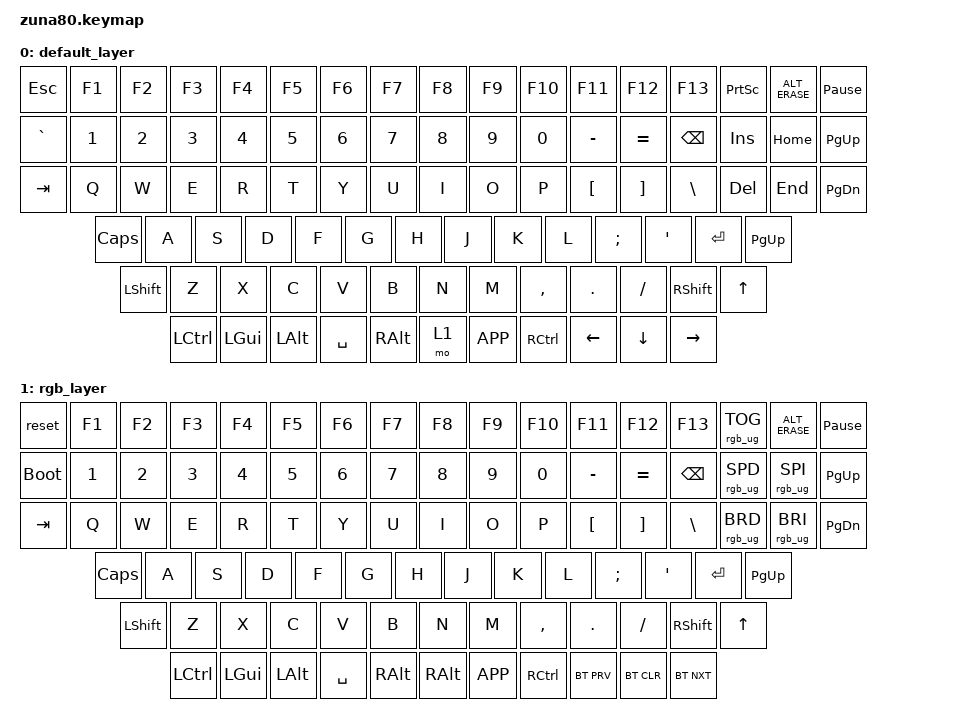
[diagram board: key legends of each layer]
/*
 * Copyright (c) 2021 Nick Winanschosen
 *
 * SPDX-License-Identifier: MIT
 */

#include <behaviors.dtsi>
#include <dt-bindings/zmk/keys.h>
#include <dt-bindings/zmk/rgb.h>
#include <dt-bindings/zmk/bt.h>
#include <dt-bindings/zmk/outputs.h>

/ {
	keymap {
		compatible = "zmk,keymap";
		
		 default_layer {
             bindings = <
        &kp ESC     &kp F1 &kp F2 &kp F3 &kp F4 &kp F5 &kp F6 &kp F7 &kp F8 &kp F9 &kp F10 &kp F11 &kp F12 &kp F13       &kp PSCRN &kp ALT_ERASE &kp PAUSE_BREAK
	&kp GRAVE  &kp N1 &kp N2 &kp N3 &kp N4 &kp N5 &kp N6 &kp N7 &kp N8 &kp N9 &kp N0 &kp MINUS &kp EQUAL  &kp BSPC      &kp INS &kp HOME &kp PG_UP
	&kp TAB  &kp Q  &kp W  &kp E  &kp R  &kp T  &kp Y  &kp U  &kp I  &kp O  &kp P  &kp LBKT  &kp RBKT  &kp BSLH          &kp DEL &kp END &kp PG_DN
	&kp CLCK  &kp A  &kp S  &kp D  &kp F  &kp G  &kp H  &kp J  &kp K  &kp L  &kp SEMI &kp SQT &kp RET &kp PG_UP
	&kp LSHFT   &kp Z  &kp X  &kp C  &kp V  &kp B  &kp N  &kp M  &kp COMMA &kp DOT &kp FSLH   &kp RSHFT                           &kp UP 
	&kp LCTRL &kp LGUI &kp LALT             &kp SPACE                     &kp RALT    &mo 1   &kp K_APP &kp RCTRL        &kp LEFT &kp DOWN &kp RIGHT
			>;
		

            
		};

		rgb_layer {
// ------------------------------------------------------------------------------------------------
// | BT CLR | F1  | F2  | F3  | F4  | F5  | F6  | F7  | F8  | F9  | F10  | F11 | F12 | EFFECT REV |
// |  BT 1   |   |  UP |   | HUEUP | SATUP | BRIUP | SPDUP |   |     |    |     |     |           |
// |   BT 2   | LT |  DN  | RT | HUEDN | SATDN | BRIDN | SPDDN |   |     |   |     |  EFFECT FORW |
// |    BT 3     |     |      |      |     |     |     |     |     |     |     |                  |
// |   BT 4  |      |      |             TOG RGB                | PRT SCR |       |       |  DEL  |
// ------------------------------------------------------------------------------------------------
			bindings = <
	&reset     &kp F1 &kp F2 &kp F3 &kp F4 &kp F5 &kp F6 &kp F7 &kp F8 &kp F9 &kp F10 &kp F11 &kp F12 &kp F13       &rgb_ug RGB_TOG&kp ALT_ERASE &kp PAUSE_BREAK
	&bootloader  &kp N1 &kp N2 &kp N3 &kp N4 &kp N5 &kp N6 &kp N7 &kp N8 &kp N9 &kp N0 &kp MINUS &kp EQUAL  &kp BSPC     &rgb_ug RGB_SPD &rgb_ug RGB_SPI &kp PG_UP
	&kp TAB  &kp Q  &kp W  &kp E  &kp R  &kp T  &kp Y  &kp U  &kp I  &kp O  &kp P  &kp LBKT  &kp RBKT  &kp BSLH          &rgb_ug RGB_BRD &rgb_ug RGB_BRI &kp PG_DN
	&kp CLCK  &kp A  &kp S  &kp D  &kp F  &kp G  &kp H  &kp J  &kp K  &kp L  &kp SEMI &kp SQT &kp RET &kp PG_UP
	&kp LSHFT   &kp Z  &kp X  &kp C  &kp V  &kp B  &kp N  &kp M  &kp COMMA &kp DOT &kp FSLH   &kp RSHFT                           &kp UP 
	&kp LCTRL &kp LGUI &kp LALT             &kp SPACE                     &kp RALT  &kp RALT     &kp K_APP &kp RCTRL        &bt BT_PRV &bt BT_CLR &bt BT_NXT
			>;
		};
	};
};

